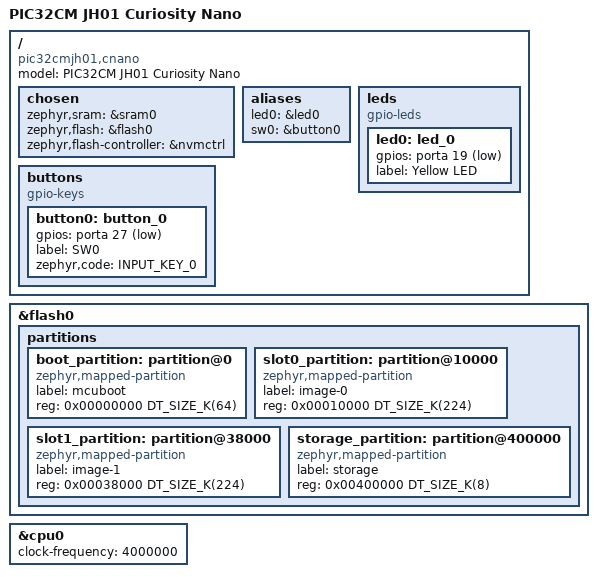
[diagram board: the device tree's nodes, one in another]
/*
 * Copyright (c) 2025 Microchip Technology Inc.
 *
 * SPDX-License-Identifier: Apache-2.0
 */

/dts-v1/;
#include <microchip/pic32c/pic32cm_jh/pic32cm_jh01/pic32cm5164jh01048.dtsi>
#include <zephyr/dt-bindings/input/input-event-codes.h>

/ {
	model = "PIC32CM JH01 Curiosity Nano";
	compatible = "pic32cmjh01,cnano", "microchip,pic32cm5164jh01048", "microchip,pic32cm";

	chosen {
		zephyr,sram = &sram0;
		zephyr,flash = &flash0;
		zephyr,flash-controller = &nvmctrl;
	};

	aliases {
		led0 = &led0;
		sw0 = &button0;
	};

	leds {
		compatible = "gpio-leds";

		led0: led_0 {
			gpios = <&porta 19 GPIO_ACTIVE_LOW>;
			label = "Yellow LED";
		};
	};

	buttons {
		compatible = "gpio-keys";

		button0: button_0 {
			gpios = <&porta 27 (GPIO_PULL_UP | GPIO_ACTIVE_LOW)>;
			label = "SW0";
			zephyr,code = <INPUT_KEY_0>;
		};
	};
};

&flash0 {
	#address-cells = <1>;
	#size-cells = <1>;

	partitions {
		#address-cells = <1>;
		#size-cells = <1>;
		ranges;

		/* Initial 64kB for boot partition*/
		boot_partition: partition@0 {
			compatible = "zephyr,mapped-partition";
			label = "mcuboot";
			reg = <0x00000000 DT_SIZE_K(64)>;
		};

		/* 224kB for slot0 partition */
		slot0_partition: partition@10000 {
			compatible = "zephyr,mapped-partition";
			label = "image-0";
			reg = <0x00010000 DT_SIZE_K(224)>;
		};

		/* 224kB for slot1 partition */
		slot1_partition: partition@38000 {
			compatible = "zephyr,mapped-partition";
			label = "image-1";
			reg = <0x00038000 DT_SIZE_K(224)>;
		};

		/* Entire 8kB of Data flash is for storage partition */
		storage_partition: partition@400000 {
			compatible = "zephyr,mapped-partition";
			label = "storage";
			reg = <0x00400000 DT_SIZE_K(8)>;
		};
	};
};

&cpu0 {
	clock-frequency = <4000000>;
};
